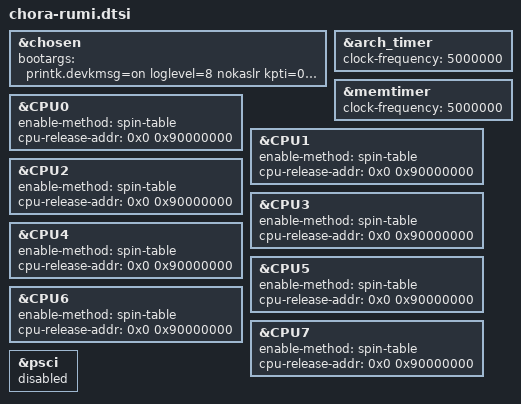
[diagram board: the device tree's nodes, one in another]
// SPDX-License-Identifier: BSD-3-Clause
/*
 * Copyright (c) Qualcomm Technologies, Inc. and/or its subsidiaries.
 */

&chosen {
	bootargs = "printk.devkmsg=on loglevel=8 nokaslr kpti=0 log_buf_len=256K swiotlb=0 slub_debug=- cpufreq.default_governor=performance";
};

&arch_timer {
	clock-frequency = <5000000>;
};

&memtimer {
	clock-frequency = <5000000>;
};

&CPU0 {
	enable-method = "spin-table"; /* TODO: Update to psci */
	cpu-release-addr = <0x0 0x90000000>;
};

&CPU1 {
	enable-method = "spin-table"; /* TODO: Update to psci */
	cpu-release-addr = <0x0 0x90000000>;
};

&CPU2 {
	enable-method = "spin-table"; /* TODO: Update to psci */
	cpu-release-addr = <0x0 0x90000000>;
};

&CPU3 {
	enable-method = "spin-table"; /* TODO: Update to psci */
	cpu-release-addr = <0x0 0x90000000>;
};

&CPU4 {
	enable-method = "spin-table"; /* TODO: Update to psci */
	cpu-release-addr = <0x0 0x90000000>;
};

&CPU5 {
	enable-method = "spin-table"; /* TODO: Update to psci */
	cpu-release-addr = <0x0 0x90000000>;
};

&CPU6 {
	enable-method = "spin-table"; /* TODO: Update to psci */
	cpu-release-addr = <0x0 0x90000000>;
};

&CPU7 {
	enable-method = "spin-table"; /* TODO: Update to psci */
	cpu-release-addr = <0x0 0x90000000>;
};

&psci {
	status = "disabled";
};
